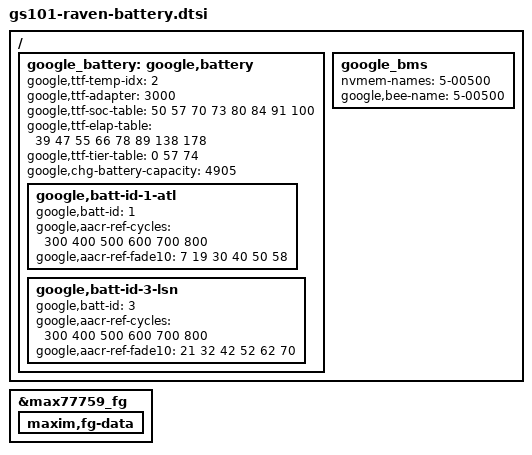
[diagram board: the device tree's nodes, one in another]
// SPDX-License-Identifier: GPL-2.0-only
/*
 * Battery device tree entries specific to raven
 *
 * Copyright 2021 Google,LLC
 *
 */

&google_battery {
	google,chg-battery-capacity = <4905>;
};

&max77759_fg {
	maxim,fg-data {
		#include "gs101-raven-battery-data.dtsi"
	};
};

/ {
	fragment@battery {
		target-path = "/";
		__overlay__ {
			google_battery: google,battery {
				google,ttf-temp-idx= <2>;
				google,ttf-adapter = <3000>;
				google,ttf-soc-table =  <50 57 70 73 80 84  91 100>;
				google,ttf-elap-table = <39 47 55 66 78 89 138 178>;
				google,ttf-tier-table = <0 57 74>;

				google,batt-id-1-atl {
					google,batt-id = <1>;
					google,aacr-ref-cycles = <300 400 500 600 700 800>;
					google,aacr-ref-fade10 = <7   19  30  40  50  58>;
				};

				google,batt-id-3-lsn {
					google,batt-id = <3>;
					google,aacr-ref-cycles = <300 400 500 600 700 800>;
					google,aacr-ref-fade10 = <21  32  42  52  62  70>;
				};
			};

			google_bms {
				nvmem-names = "5-00500";
				/* pack eeprom is available only with P20+ batteries */
				google,bee-name = "5-00500";
			};
		};
	};
};
